# F28x7x_dcsm_common_regs register map
Vendor: Texas Instruments
Peripheral module from a debugger description file (folder C2000).
Address unit: 16 bits
Registers are 32-bit, read-only, no defined reset value unless marked. A register's access mark holds for its fields unless they carry their own. Offsets are as the file gives them; lines under a group give offsets from that group; [hi:lo] are bit positions; {n}, {i} and the like mark numbered series; 'fields as' and 'values as' point back to an identical list; <NAME> marks a mode.

## DCSM_COMMON_REGS — DCSM COMMON Registers
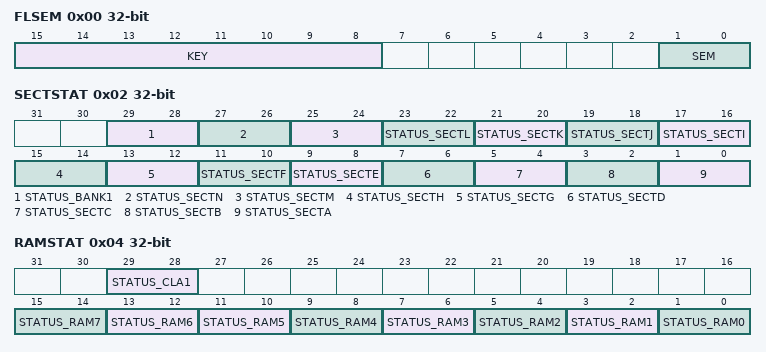
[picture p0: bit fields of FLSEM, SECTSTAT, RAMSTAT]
0x00 FLSEM access not given — Flash Wrapper Semaphore Register
  [15:8] KEY — Semaphore Key (access R=0/W)
  [1:0] SEM rw — Flash Semaphore Bit
0x02 SECTSTAT — Sectors Status Register
  [29:28] STATUS_BANK1 — Zone Status Flash BANK1
  [27:26] STATUS_SECTN — Zone Status Flash Sector N
  [25:24] STATUS_SECTM — Zone Status Flash Sector M
  [23:22] STATUS_SECTL — Zone Status Flash Sector L
  [21:20] STATUS_SECTK — Zone Status Flash Sector K
  [19:18] STATUS_SECTJ — Zone Status Flash Sector J
  [17:16] STATUS_SECTI — Zone Status Flash Sector I
  [15:14] STATUS_SECTH — Zone Status Flash Sector H
  [13:12] STATUS_SECTG — Zone Status Flash Sector G
  [11:10] STATUS_SECTF — Zone Status Flash Sector F
  [9:8] STATUS_SECTE — Zone Status Flash Sector E
  [7:6] STATUS_SECTD — Zone Status Flash Sector D
  [5:4] STATUS_SECTC — Zone Status Flash Sector C
  [3:2] STATUS_SECTB — Zone Status Flash Sector B
  [1:0] STATUS_SECTA — Zone Status Flash Sector A
0x04 RAMSTAT — RAM Status Register
  [29:28] STATUS_CLA1 — Zone Status CLA1
  [15:14] STATUS_RAM7 — Zone Status RAM D1
  [13:12] STATUS_RAM6 — Zone Status RAM D0
  [2n+1:2n] STATUS_RAM{n} (n=0..5) — Zone Status RAM LS{n}
